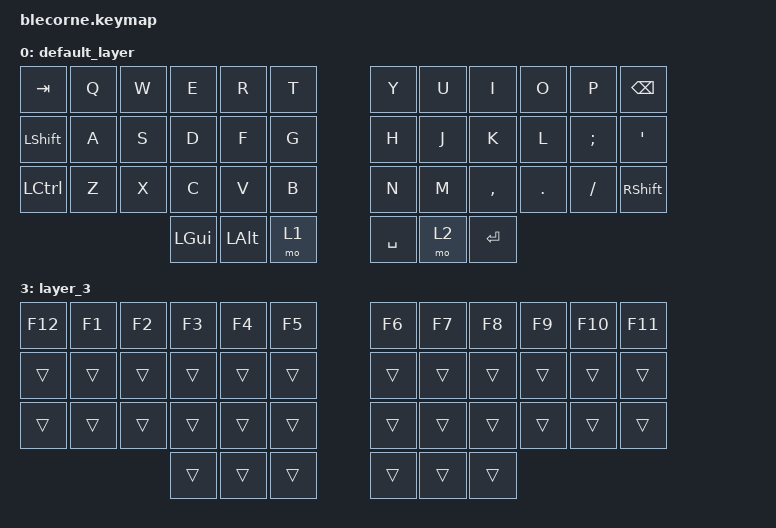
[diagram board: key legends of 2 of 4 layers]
/*
 * Copyright (c) 2020 The ZMK Contributors
 * SPDX-License-Identifier: MIT
 */

#include <behaviors.dtsi>
#include <dt-bindings/zmk/keys.h>
#include <dt-bindings/zmk/bt.h>


/ {
    chosen {
        zmk,physical-layout = &foostan_corne_6col_layout;

        // zmk,physical-layout = &foostan_corne_5col_layout;
    };
};

/ {
    keymap {
        compatible = "zmk,keymap";

        default_layer {
            bindings = <
&kp TAB         &kp Q  &kp W  &kp E     &kp R         &kp T    &kp Y      &kp U  &kp I      &kp O    &kp P     &kp BSPC
&kp LEFT_SHIFT  &kp A  &kp S  &kp D     &kp F         &kp G    &kp H      &kp J  &kp K      &kp L    &kp SEMI  &kp SINGLE_QUOTE
&kp LCTRL       &kp Z  &kp X  &kp C     &kp V         &kp B    &kp N      &kp M  &kp COMMA  &kp DOT  &kp FSLH  &kp RIGHT_SHIFT
                              &kp LGUI  &kp LEFT_ALT  &mo 1    &kp SPACE  &mo 2  &kp ENTER
            >;
        };

        lower_layer {
            bindings = <
&kp ESCAPE      &kp N1     &kp N2     &kp N3      &kp N4     &kp N5    &kp N6     &kp N7                &kp N8                 &kp N9            &kp N0             &kp BACKSPACE
&kp LEFT_SHIFT  &kp TILDE  &kp GRAVE  &kp DELETE  &kp ENTER  &trans    &kp UNDER  &kp LEFT_PARENTHESIS  &kp RIGHT_PARENTHESIS  &kp LEFT_BRACKET  &kp RIGHT_BRACKET  &kp ENTER
&trans          &trans     &trans     &trans      &trans     &trans    &trans     &kp LEFT_BRACE        &kp RIGHT_BRACE        &trans            &trans             &kp LEFT_SHIFT
                                      &trans      &trans     &trans    &mo 3      &kp RALT
            >;
        };

        raise_layer {
            bindings = <
&kp GRAVE       &kp EXCL      &kp AT        &kp HASH      &kp DLLR      &kp PRCNT     &kp CARET  &kp AMPS  &kp ASTRK  &kp MINUS  &kp EQUAL  &kp BSLH
&kp LEFT_SHIFT  &trans        &trans        &trans        &trans        &trans        &kp LEFT   &kp DOWN  &kp UP     &kp RIGHT  &trans     &kp ENTER
&kp LCTRL       &bt BT_SEL 3  &bt BT_SEL 2  &bt BT_SEL 1  &bt BT_SEL 0  &bt BT_CLR    &trans     &trans    &trans     &trans     &trans     &kp RIGHT_SHIFT
                                            &trans        &trans        &trans        &trans     &trans
            >;
        };

        layer_3 {
            bindings = <
&kp F12  &kp F1  &kp F2  &kp F3  &kp F4  &kp F5    &kp F6  &kp F7  &kp F8  &kp F9  &kp F10  &kp F11
&trans   &trans  &trans  &trans  &trans  &trans    &trans  &trans  &trans  &trans  &trans   &trans
&trans   &trans  &trans  &trans  &trans  &trans    &trans  &trans  &trans  &trans  &trans   &trans
                         &trans  &trans  &trans    &trans  &trans  &trans
            >;
        };
    };
};


